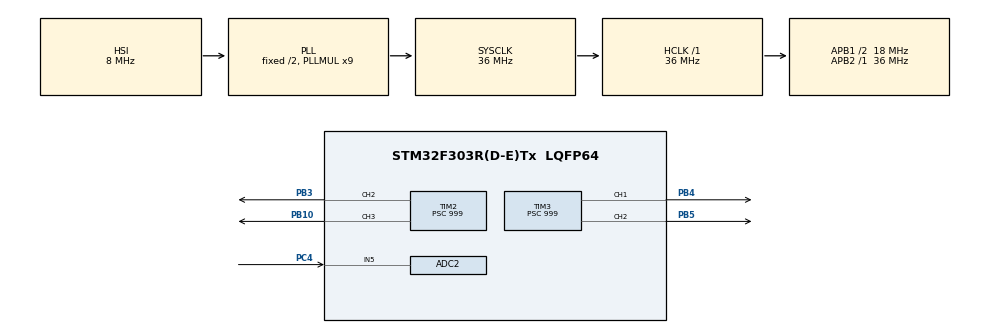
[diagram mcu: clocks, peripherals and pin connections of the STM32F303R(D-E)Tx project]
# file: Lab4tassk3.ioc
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ADC2.Channel-0\#ChannelRegularConversion=ADC_CHANNEL_5
ADC2.NbrOfConversionFlag=1
ADC2.Offset-0\#ChannelRegularConversion=0
ADC2.OffsetNumber-0\#ChannelRegularConversion=ADC_OFFSET_NONE
ADC2.Rank-0\#ChannelRegularConversion=1
ADC2.SamplingTime-0\#ChannelRegularConversion=ADC_SAMPLETIME_1CYCLE_5
ADC2.SamplingTimeOPAMP-0\#ChannelRegularConversion=ADC_SAMPLETIME_19CYCLES_5
Mcu.Family=STM32F3
Mcu.Name=STM32F303R(D-E)Tx
Mcu.Package=LQFP64
NVIC.PriorityGroup=NVIC_PRIORITYGROUP_0
PB10.Signal=S_TIM2_CH3
PB3.Signal=S_TIM2_CH2
PB4.Signal=S_TIM3_CH1
PB5.Signal=S_TIM3_CH2
PC4.Mode=IN5-Single-Ended
PC4.Signal=ADC2_IN5
ProjectManager.HeapSize=0x200
ProjectManager.StackSize=0x400
ProjectManager.TargetToolchain=STM32CubeIDE
RCC.AHBFreq_Value=36000000
RCC.APB1CLKDivider=RCC_HCLK_DIV2
RCC.APB1Freq_Value=18000000
RCC.APB1TimFreq_Value=36000000
RCC.APB2Freq_Value=36000000
RCC.APB2TimFreq_Value=36000000
RCC.CortexFreq_Value=36000000
RCC.HCLKFreq_Value=36000000
RCC.HSE_VALUE=8000000
RCC.HSI_VALUE=8000000
RCC.PLLM=8
RCC.PLLMUL=RCC_PLL_MUL9
RCC.PLLN=336
RCC.PLLP=RCC_PLLP_DIV4
RCC.PLLQ=7
RCC.RCC_PLLsource_Clock_Source_FROM_HSE=RCC_HSE_PREDIV_DIV2
RCC.SYSCLKFreq_VALUE=36000000
RCC.SYSCLKSourceVirtual=RCC_SYSCLKSOURCE_PLLCLK
RCC.USBFreq_Value=36000000
SH.S_TIM2_CH2.0=TIM2_CH2,PWM Generation2 CH2
SH.S_TIM2_CH3.0=TIM2_CH3,PWM Generation3 CH3
SH.S_TIM3_CH1.0=TIM3_CH1,PWM Generation1 CH1
SH.S_TIM3_CH2.0=TIM3_CH2,PWM Generation2 CH2
TIM2.Channel-PWM\ Generation2\ CH2=TIM_CHANNEL_2
TIM2.Channel-PWM\ Generation3\ CH3=TIM_CHANNEL_3
TIM2.Period=1151
TIM2.Prescaler=999
TIM2.Pulse-PWM\ Generation2\ CH2=115
TIM2.Pulse-PWM\ Generation3\ CH3=115
TIM3.Channel-PWM\ Generation1\ CH1=TIM_CHANNEL_1
TIM3.Channel-PWM\ Generation2\ CH2=TIM_CHANNEL_2
TIM3.Period=1151
TIM3.Prescaler=999
TIM3.Pulse-PWM\ Generation1\ CH1=115
TIM3.Pulse-PWM\ Generation2\ CH2=115
VP_TIM2_VS_ClockSourceINT.Mode=Internal
VP_TIM3_VS_ClockSourceINT.Mode=Internal
board=NUCLEO-F303RE

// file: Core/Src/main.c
/* USER CODE BEGIN Header */
/**
  ******************************************************************************
  * @file           : main.c
  * @brief          : Main program body
  ******************************************************************************
  * @attention
  *
  * Copyright (c) 2025 STMicroelectronics.
  * All rights reserved.
  *
  * This software is licensed under terms that can be found in the LICENSE file
  * in the root directory of this software component.
  * If no LICENSE file comes with this software, it is provided AS-IS.
  *
  ******************************************************************************
  */
/* USER CODE END Header */
#include "main.h"

ADC_HandleTypeDef hadc2;

TIM_HandleTypeDef htim2;
TIM_HandleTypeDef htim3;

void SystemClock_Config(void);
static void MX_GPIO_Init(void);
static void MX_ADC2_Init(void);
static void MX_TIM2_Init(void);
static void MX_TIM3_Init(void);

int main(void)
{

  /* MCU Configuration--------------------------------------------------------*/

  /* Reset of all peripherals, Initializes the Flash interface and the Systick. */
  HAL_Init();

  /* Configure the system clock */
  SystemClock_Config();

  /* Initialize all configured peripherals */
  MX_GPIO_Init();
  MX_ADC2_Init();
  MX_TIM2_Init();
  MX_TIM3_Init();
  /* USER CODE BEGIN 2 */

  HAL_TIM_PWM_Start(&htim2, TIM_CHANNEL_3); // D1
  HAL_TIM_PWM_Start(&htim3, TIM_CHANNEL_1); // D2
  HAL_TIM_PWM_Start(&htim3, TIM_CHANNEL_2); // D3
  HAL_TIM_PWM_Start(&htim2, TIM_CHANNEL_2); // D4

  /* USER CODE END 2 */

  /* Infinite loop */
  while (1)
  {

    /* USER CODE BEGIN 3 */

	  HAL_ADC_Start(&hadc2);

	  HAL_ADC_PollForConversion(&hadc2, 1);

	  uint16_t adc_value = HAL_ADC_GetValue(&hadc2);

	  TIM2->CCR3 = (1151-adc_value);
	  TIM3->CCR1 = (1151-adc_value);
	  TIM3->CCR2 = (1151-adc_value);
	  TIM2->CCR2 = (1151-adc_value);
  }
  /* USER CODE END 3 */
}

void SystemClock_Config(void)
{
  RCC_OscInitTypeDef RCC_OscInitStruct = {0};
  RCC_ClkInitTypeDef RCC_ClkInitStruct = {0};
  RCC_PeriphCLKInitTypeDef PeriphClkInit = {0};

  /** Initializes the RCC Oscillators according to the specified parameters
  * in the RCC_OscInitTypeDef structure.
  */
  RCC_OscInitStruct.OscillatorType = RCC_OSCILLATORTYPE_HSI;
  RCC_OscInitStruct.HSIState = RCC_HSI_ON;
  RCC_OscInitStruct.HSICalibrationValue = RCC_HSICALIBRATION_DEFAULT;
  RCC_OscInitStruct.PLL.PLLState = RCC_PLL_ON;
  RCC_OscInitStruct.PLL.PLLSource = RCC_PLLSOURCE_HSI;
  RCC_OscInitStruct.PLL.PLLMUL = RCC_PLL_MUL9;
  RCC_OscInitStruct.PLL.PREDIV = RCC_PREDIV_DIV1;
  if (HAL_RCC_OscConfig(&RCC_OscInitStruct) != HAL_OK)
  {
    Error_Handler();
  }

  /** Initializes the CPU, AHB and APB buses clocks
  */
  RCC_ClkInitStruct.ClockType = RCC_CLOCKTYPE_HCLK|RCC_CLOCKTYPE_SYSCLK
                              |RCC_CLOCKTYPE_PCLK1|RCC_CLOCKTYPE_PCLK2;
  RCC_ClkInitStruct.SYSCLKSource = RCC_SYSCLKSOURCE_PLLCLK;
  RCC_ClkInitStruct.AHBCLKDivider = RCC_SYSCLK_DIV1;
  RCC_ClkInitStruct.APB1CLKDivider = RCC_HCLK_DIV2;
  RCC_ClkInitStruct.APB2CLKDivider = RCC_HCLK_DIV1;

  if (HAL_RCC_ClockConfig(&RCC_ClkInitStruct, FLASH_LATENCY_1) != HAL_OK)
  {
    Error_Handler();
  }
  PeriphClkInit.PeriphClockSelection = RCC_PERIPHCLK_ADC12|RCC_PERIPHCLK_TIM2
                              |RCC_PERIPHCLK_TIM34;
  PeriphClkInit.Adc12ClockSelection = RCC_ADC12PLLCLK_DIV1;
  PeriphClkInit.Tim2ClockSelection = RCC_TIM2CLK_HCLK;
  PeriphClkInit.Tim34ClockSelection = RCC_TIM34CLK_HCLK;
  if (HAL_RCCEx_PeriphCLKConfig(&PeriphClkInit) != HAL_OK)
  {
    Error_Handler();
  }
}

static void MX_ADC2_Init(void)
{

  ADC_ChannelConfTypeDef sConfig = {0};

  /** Common config
  */
  hadc2.Instance = ADC2;
  hadc2.Init.ClockPrescaler = ADC_CLOCK_ASYNC_DIV1;
  hadc2.Init.Resolution = ADC_RESOLUTION_12B;
  hadc2.Init.ScanConvMode = ADC_SCAN_DISABLE;
  hadc2.Init.ContinuousConvMode = DISABLE;
  hadc2.Init.DiscontinuousConvMode = DISABLE;
  hadc2.Init.ExternalTrigConvEdge = ADC_EXTERNALTRIGCONVEDGE_NONE;
  hadc2.Init.ExternalTrigConv = ADC_SOFTWARE_START;
  hadc2.Init.DataAlign = ADC_DATAALIGN_RIGHT;
  hadc2.Init.NbrOfConversion = 1;
  hadc2.Init.DMAContinuousRequests = DISABLE;
  hadc2.Init.EOCSelection = ADC_EOC_SINGLE_CONV;
  hadc2.Init.LowPowerAutoWait = DISABLE;
  hadc2.Init.Overrun = ADC_OVR_DATA_OVERWRITTEN;
  if (HAL_ADC_Init(&hadc2) != HAL_OK)
  {
    Error_Handler();
  }

  /** Configure Regular Channel
  */
  sConfig.Channel = ADC_CHANNEL_5;
  sConfig.Rank = ADC_REGULAR_RANK_1;
  sConfig.SingleDiff = ADC_SINGLE_ENDED;
  sConfig.SamplingTime = ADC_SAMPLETIME_1CYCLE_5;
  sConfig.OffsetNumber = ADC_OFFSET_NONE;
  sConfig.Offset = 0;
  if (HAL_ADC_ConfigChannel(&hadc2, &sConfig) != HAL_OK)
  {
    Error_Handler();
  }

}

static void MX_TIM2_Init(void)
{

  TIM_ClockConfigTypeDef sClockSourceConfig = {0};
  TIM_MasterConfigTypeDef sMasterConfig = {0};
  TIM_OC_InitTypeDef sConfigOC = {0};

  htim2.Instance = TIM2;
  htim2.Init.Prescaler = 999;
  htim2.Init.CounterMode = TIM_COUNTERMODE_UP;
  htim2.Init.Period = 1151;
  htim2.Init.ClockDivision = TIM_CLOCKDIVISION_DIV1;
  htim2.Init.AutoReloadPreload = TIM_AUTORELOAD_PRELOAD_DISABLE;
  if (HAL_TIM_Base_Init(&htim2) != HAL_OK)
  {
    Error_Handler();
  }
  sClockSourceConfig.ClockSource = TIM_CLOCKSOURCE_INTERNAL;
  if (HAL_TIM_ConfigClockSource(&htim2, &sClockSourceConfig) != HAL_OK)
  {
    Error_Handler();
  }
  if (HAL_TIM_PWM_Init(&htim2) != HAL_OK)
  {
    Error_Handler();
  }
  sMasterConfig.MasterOutputTrigger = TIM_TRGO_RESET;
  sMasterConfig.MasterSlaveMode = TIM_MASTERSLAVEMODE_DISABLE;
  if (HAL_TIMEx_MasterConfigSynchronization(&htim2, &sMasterConfig) != HAL_OK)
  {
    Error_Handler();
  }
  sConfigOC.OCMode = TIM_OCMODE_PWM1;
  sConfigOC.Pulse = 115;
  sConfigOC.OCPolarity = TIM_OCPOLARITY_HIGH;
  sConfigOC.OCFastMode = TIM_OCFAST_DISABLE;
  if (HAL_TIM_PWM_ConfigChannel(&htim2, &sConfigOC, TIM_CHANNEL_2) != HAL_OK)
  {
    Error_Handler();
  }
  if (HAL_TIM_PWM_ConfigChannel(&htim2, &sConfigOC, TIM_CHANNEL_3) != HAL_OK)
  {
    Error_Handler();
  }
  HAL_TIM_MspPostInit(&htim2);

}

static void MX_TIM3_Init(void)
{

  TIM_ClockConfigTypeDef sClockSourceConfig = {0};
  TIM_MasterConfigTypeDef sMasterConfig = {0};
  TIM_OC_InitTypeDef sConfigOC = {0};

  htim3.Instance = TIM3;
  htim3.Init.Prescaler = 999;
  htim3.Init.CounterMode = TIM_COUNTERMODE_UP;
  htim3.Init.Period = 1151;
  htim3.Init.ClockDivision = TIM_CLOCKDIVISION_DIV1;
  htim3.Init.AutoReloadPreload = TIM_AUTORELOAD_PRELOAD_DISABLE;
  if (HAL_TIM_Base_Init(&htim3) != HAL_OK)
  {
    Error_Handler();
  }
  sClockSourceConfig.ClockSource = TIM_CLOCKSOURCE_INTERNAL;
  if (HAL_TIM_ConfigClockSource(&htim3, &sClockSourceConfig) != HAL_OK)
  {
    Error_Handler();
  }
  if (HAL_TIM_PWM_Init(&htim3) != HAL_OK)
  {
    Error_Handler();
  }
  sMasterConfig.MasterOutputTrigger = TIM_TRGO_RESET;
  sMasterConfig.MasterSlaveMode = TIM_MASTERSLAVEMODE_DISABLE;
  if (HAL_TIMEx_MasterConfigSynchronization(&htim3, &sMasterConfig) != HAL_OK)
  {
    Error_Handler();
  }
  sConfigOC.OCMode = TIM_OCMODE_PWM1;
  sConfigOC.Pulse = 115;
  sConfigOC.OCPolarity = TIM_OCPOLARITY_HIGH;
  sConfigOC.OCFastMode = TIM_OCFAST_DISABLE;
  if (HAL_TIM_PWM_ConfigChannel(&htim3, &sConfigOC, TIM_CHANNEL_1) != HAL_OK)
  {
    Error_Handler();
  }
  if (HAL_TIM_PWM_ConfigChannel(&htim3, &sConfigOC, TIM_CHANNEL_2) != HAL_OK)
  {
    Error_Handler();
  }
  HAL_TIM_MspPostInit(&htim3);

}

static void MX_GPIO_Init(void)
{

  /* GPIO Ports Clock Enable */
  __HAL_RCC_GPIOC_CLK_ENABLE();
  __HAL_RCC_GPIOB_CLK_ENABLE();

}

void Error_Handler(void)
{
  __disable_irq();
  while (1)
  {
  }
}
